# ATSAMRH707F18A register map
Vendor: Microchip Technology; Series: SAMRH707; File version: 0
CPU: CM7 r1p1, little endian, MPU, FPU, double-precision FPU, I-cache, D-cache, ITCM, DTCM, 3 interrupt priority bits, 69 interrupts
Registers are 32-bit, read-write, reset 0x0 unless marked. A register's access mark holds for its fields unless they carry their own. Offsets are from the block's base; [hi:lo] are bit positions; {n}, {i} and the like mark numbered series; 'fields as' and 'values as' point back to an identical list.

## IP1553
Base 0x4003C000
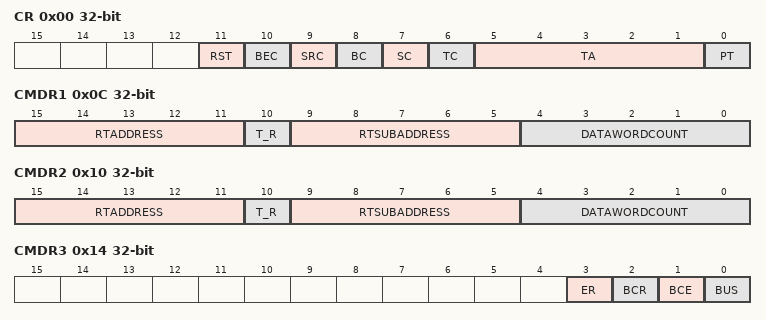
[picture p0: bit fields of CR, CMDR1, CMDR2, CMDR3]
0x00 CR — Configuration Register
  [11] RST — Soft Reset
  [10] BEC — BCEnableCmd
  [9] SRC — SREQBitCmd
  [8] BC — BusyBitCmd
  [7] SC — SSBitCmd
  [6] TC — TRBitCmd
  [5:1] TA — TermAddressConf
  [0] PT — POTermConf
0x0C CMDR1 wo — Command Register 1
  [15:11] RTADDRESS, [10] T_R, [9:5] RTSUBADDRESS, [4:0] DATAWORDCOUNT
0x10 CMDR2 wo — Command Register 2
  [15:11] RTADDRESS
  [10] T_R — R/T
  [9:5] RTSUBADDRESS
  [4:0] DATAWORDCOUNT
0x14 CMDR3 wo — Command Register 3
  [3] ER — data or command transfer
  [2] BCR — 1553 receiver
  [1] BCE — 1553 emitter
  [0] BUS — bus used
0x18 BITR wo — BIT Register
  [15:0] TOBITWORD
0x1C VWR wo — Vector Word Register
  [15:0] TOVECTORWORD
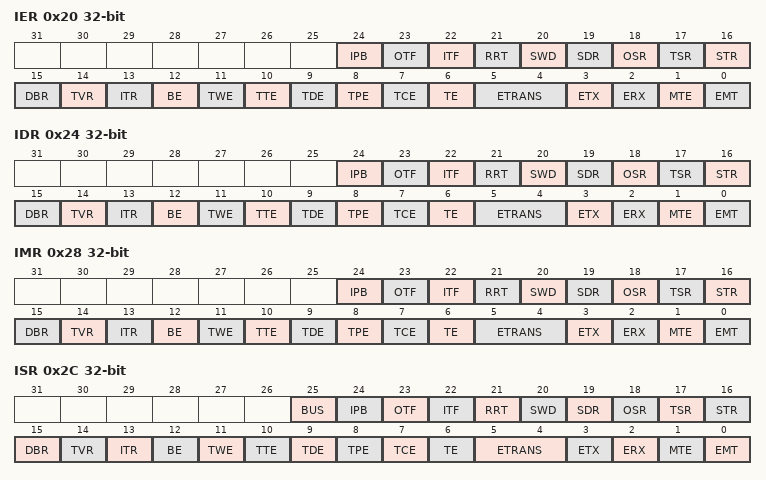
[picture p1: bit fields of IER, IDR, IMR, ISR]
0x20 IER wo — IRQ Mask Enable Register
  [24] IPB — IPBusy
  [23] OTF — OvInhibitTermFlagReq
  [22] ITF — InhibitTermFlagReq
  [21] RRT — ResetRTReq
  [20] SWD — SyncWithoutDataReq
  [19] SDR — SyncWithDataReq
  [18] OSR — OvTranShutdownReq
  [17] TSR — TranShutdownReq
  [16] STR — InitSelfTestReq
  [15] DBR — DynamicBusContReq
  [14] TVR — TransVecWordReq
  [13] ITR — IllegalTransferReq
  [12] BE — BufIFErr
  [11] TWE — TransWordCounterErr
  [10] TTE — TransTimeOutErr
  [9] TDE — TransDataTypeErr
  [8] TPE — TransParityErr
  [7] TCE — TransCodingErr
  [6] TE — TransErr
  [5:4] ETRANS — EndTransfer
  [3] ETX — EndTransmission
  [2] ERX — End reception
  [1] MTE — MemTransferErr
  [0] EMT — EndMemTransfer
0x24 IDR wo — IRQ Mask Disable Register
  fields as IER
0x28 IMR ro — IRQ Mask Register
  fields as IER
0x2C ISR ro — IRQ Status Register
  [25] BUS — BUS activated on last transfer
  [24] IPB — IPBusy
  [23] OTF — OvInhibitTermFlagReq
  [22] ITF — InhibitTermFlagReq
  [21] RRT — ResetRTReq
  [20] SWD — SyncWithoutDataReq
  [19] SDR — SyncWithDataReq
  [18] OSR — OvTranShutdownReq
  [17] TSR — TranShutdownReq
  [16] STR — InitSelfTestReq
  [15] DBR — DynamicBusContReq
  [14] TVR — TransVecWordReq
  [13] ITR — IllegalTransferReq
  [12] BE — BufIFErr
  [11] TWE — TransWordCounterErr
  [10] TTE — TransTimeOutErr
  [9] TDE — TransDataTypeErr
  [8] TPE — TransParityErr
  [7] TCE — TransCodingErr
  [6] TE — TransErr
  [5:4] ETRANS — EndTransfer
  [3] ETX — EndTransmission
  [2] ERX — End reception
  [1] MTE — MemTransferErr
  [0] EMT — EndMemTransfer
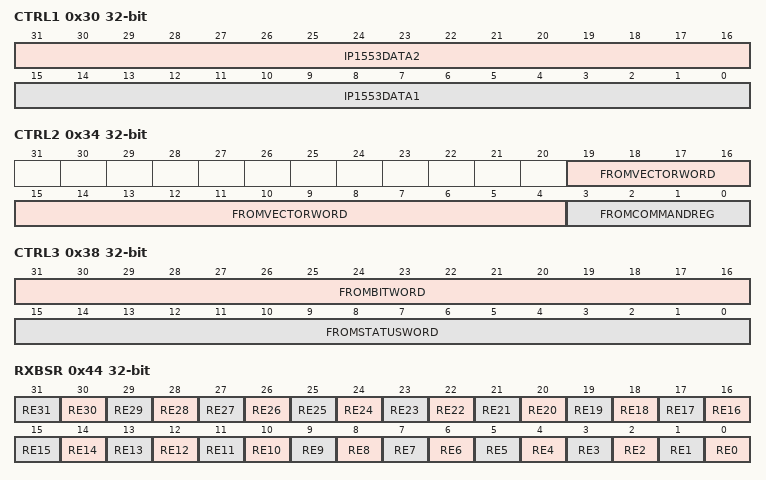
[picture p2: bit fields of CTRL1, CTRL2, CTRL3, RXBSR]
0x30 CTRL1 ro — Control Register 1
  [31:16] IP1553DATA2 — IP1553 data value 2
  [15:0] IP1553DATA1 — IP1553 data value 1
0x34 CTRL2 ro — Control Register 2
  [19:4] FROMVECTORWORD — from vector register
  [3:0] FROMCOMMANDREG — from command register
0x38 CTRL3 ro — Control Register 3
  [31:16] FROMBITWORD — content of bit word register
  [15:0] FROMSTATUSWORD — content of status word register
0x3C ARW — Address Register Write
  [31:0] REG_ADDR_APB_W — TX base address
0x40 ARR — Address Register Read
  [31:0] REG_ADDR_APB_R — RX base address
0x44 RXBSR — Rx Buffer Status Register
  [n] RE{n} (n=0..31) — Receive Buffer, {n} with x=[0-31]
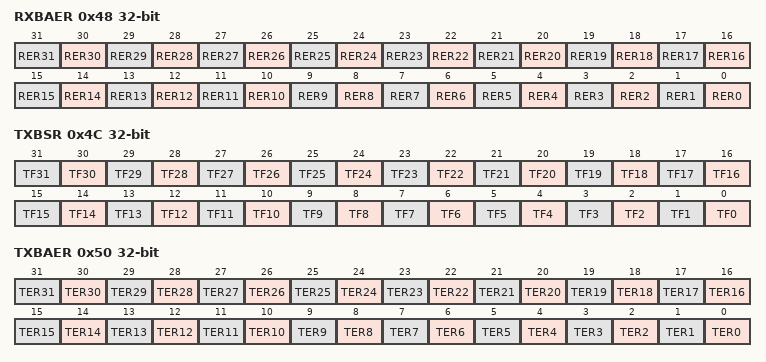
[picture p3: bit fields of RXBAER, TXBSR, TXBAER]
0x48 RXBAER — Rx Buffer Access Error Register
  [n] RER{n} (n=0..31) — Receive error {n}, x with x=[0-31]
0x4C TXBSR — Tx Buffer Status Register
  [n] TF{n} (n=0..31) — Transmit buffer {n}, x with x=[0-31]
0x50 TXBAER — Tx Buffer Access Error Register
  [n] TER{n} (n=0..31) — Transmit error {n}, x with x=[0-31]

## NMIC — Non-maskable Interrupt Controller
Base 0x400A8000
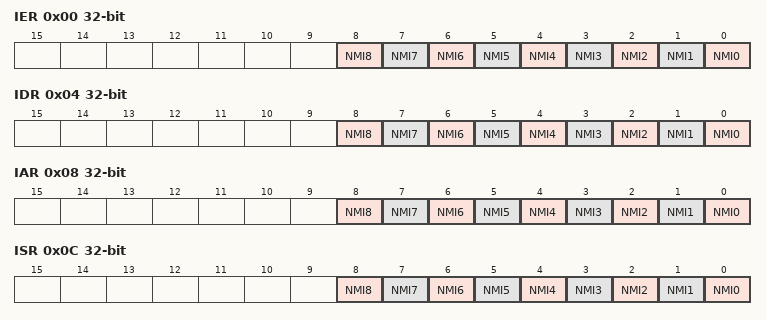
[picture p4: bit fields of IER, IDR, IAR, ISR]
0x00 IER wo — Interrupt Enable Register
  [n] NMI{n} (n=0..8) — Non-maskable Interrupt {n} Enable
0x04 IDR wo — Interrupt Disable Register
  [n] NMI{n} (n=0..8) — Non-maskable Interrupt {n} Disable
0x08 IAR ro — Interrupt Active Register
  [n] NMI{n} (n=0..8) — Active Interrupt {n}
0x0C ISR ro — Interrupt Status Register
  [n] NMI{n} (n=0..8) — Non-maskable Interrupt Source {n} Pending (cleared on read)
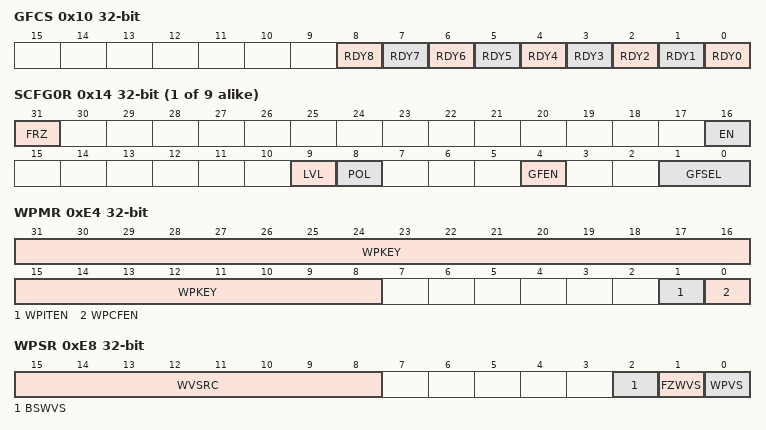
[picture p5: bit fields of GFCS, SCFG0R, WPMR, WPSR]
0x10 GFCS ro — Glitch Filter Configuration Status Register
  [n] RDY{n} (n=0..8) — Filter {n} Configuration Ready
{0x14+4i} SCFG{i}R (i=0..8) — Source Configuration Register {i}
  [31] FRZ — Interrupt Line Freeze
  [16] EN — Source Enable
  [9] LVL — Level Detection (LVL bit is read-only in NMIC_SCFG1 to 8)
  [8] POL — Polarity (POL bit is read-only in NMIC_SCFG1 to 8)
  [4] GFEN — Glitch Filter Enable (GFEN bit is read-only in NMIC_SCFG1 to 8)
  [1:0] GFSEL — Glitch Filter Selector (GFSEL field is read-only in NMIC_SCFG1 to 8)
0xE4 WPMR — Write Protection Mode Register
  [31:8] WPKEY — Write Protection Key
    0x4E4D49=PASSWD (Writing any other value in this field aborts the write operation of the WPCFEN and WPITEN bit. Always reads as 0.)
  [1] WPITEN — Write Protection Interrupt Enable
  [0] WPCFEN — Write Protection Configuration Enable
0xE8 WPSR ro — Write Protection Status Register
  [15:8] WVSRC — Write Violation Source
  [2] BSWVS — Busy Register Write Violation Status
  [1] FZWVS — Frozen Register Write Violation Status
  [0] WPVS — Write Protection Register Violation Status
